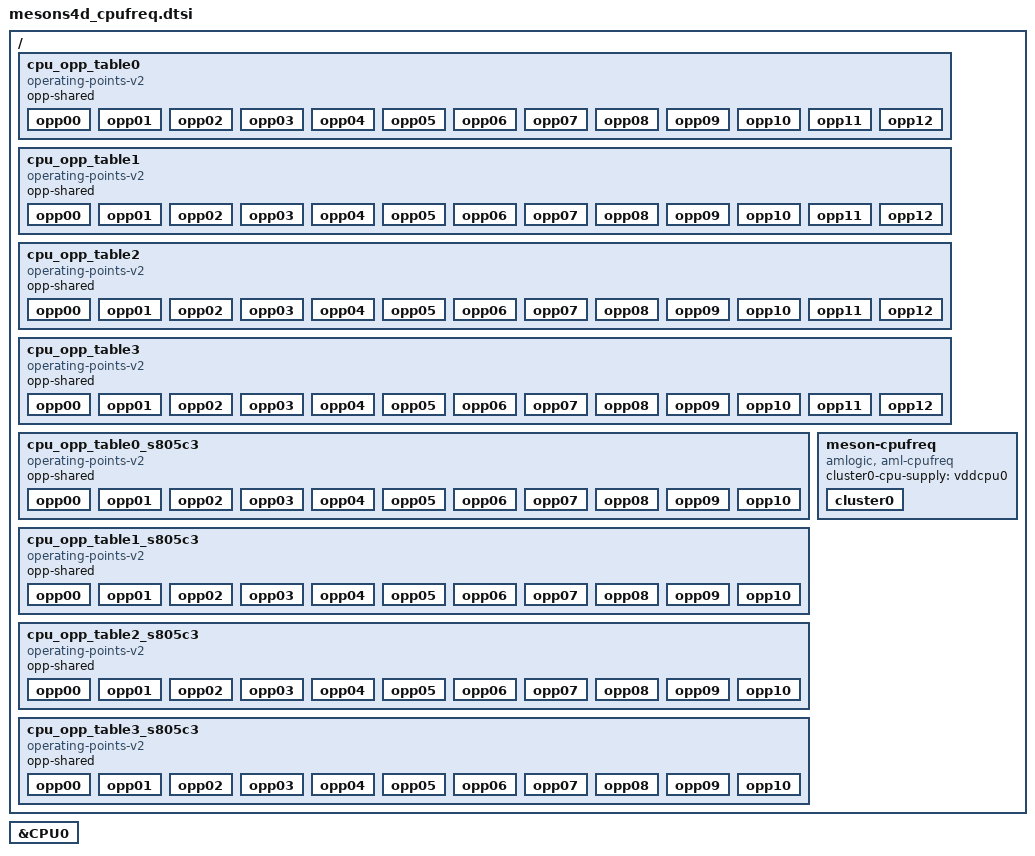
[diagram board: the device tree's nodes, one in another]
// SPDX-License-Identifier: (GPL-2.0+ OR MIT)
/*
 * Copyright (c) 2026 Amlogic, Inc. All rights reserved.
 */

/ {
	cpu_opp_table0: cpu_opp_table0 {
		compatible = "operating-points-v2";
		status = "okay";
		opp-shared;

		opp00 {
			opp-hz = /bits/ 64 <100000000>;
			opp-microvolt = <769000>;
		};
		opp01 {
			opp-hz = /bits/ 64 <250000000>;
			opp-microvolt = <769000>;
		};
		opp02 {
			opp-hz = /bits/ 64 <500000000>;
			opp-microvolt = <769000>;
		};
		opp03 {
			opp-hz = /bits/ 64 <666666666>;
			opp-microvolt = <769000>;
		};
		opp04 {
			opp-hz = /bits/ 64 <1000000000>;
			opp-microvolt = <769000>;
		};
		opp05 {
			opp-hz = /bits/ 64 <1200000000>;
			opp-microvolt = <769000>;
		};
		opp06 {
			opp-hz = /bits/ 64 <1404000000>;
			opp-microvolt = <799000>;
		};
		opp07 {
			opp-hz = /bits/ 64 <1500000000>;
			opp-microvolt = <829000>;
		};
		opp08 {
			opp-hz = /bits/ 64 <1608000000>;
			opp-microvolt = <859000>;
		};
		opp09 {
			opp-hz = /bits/ 64 <1704000000>;
			opp-microvolt = <889000>;
		};
		opp10 {
			opp-hz = /bits/ 64 <1800000000>;
			opp-microvolt = <929000>;
		};
		opp11 {
			opp-hz = /bits/ 64 <1908000000>;
			opp-microvolt = <979000>;
		};
		opp12 {
			opp-hz = /bits/ 64 <2004000000>;
			opp-microvolt = <1009000>;
		};
	};

	cpu_opp_table1: cpu_opp_table1 {
		compatible = "operating-points-v2";
		status = "okay";
		opp-shared;

		opp00 {
			opp-hz = /bits/ 64 <100000000>;
			opp-microvolt = <779000>;
		};
		opp01 {
			opp-hz = /bits/ 64 <250000000>;
			opp-microvolt = <779000>;
		};
		opp02 {
			opp-hz = /bits/ 64 <500000000>;
			opp-microvolt = <779000>;
		};
		opp03 {
			opp-hz = /bits/ 64 <666666666>;
			opp-microvolt = <779000>;
		};
		opp04 {
			opp-hz = /bits/ 64 <1000000000>;
			opp-microvolt = <779000>;
		};
		opp05 {
			opp-hz = /bits/ 64 <1200000000>;
			opp-microvolt = <779000>;
		};
		opp06 {
			opp-hz = /bits/ 64 <1404000000>;
			opp-microvolt = <799000>;
		};
		opp07 {
			opp-hz = /bits/ 64 <1500000000>;
			opp-microvolt = <829000>;
		};
		opp08 {
			opp-hz = /bits/ 64 <1608000000>;
			opp-microvolt = <859000>;
		};
		opp09 {
			opp-hz = /bits/ 64 <1704000000>;
			opp-microvolt = <889000>;
		};
		opp10 {
			opp-hz = /bits/ 64 <1800000000>;
			opp-microvolt = <929000>;
		};
		opp11 {
			opp-hz = /bits/ 64 <1908000000>;
			opp-microvolt = <979000>;
		};
		opp12 {
			opp-hz = /bits/ 64 <2004000000>;
			opp-microvolt = <1009000>;
		};
	};

	cpu_opp_table2: cpu_opp_table2 {
		compatible = "operating-points-v2";
		status = "okay";
		opp-shared;

		opp00 {
			opp-hz = /bits/ 64 <100000000>;
			opp-microvolt = <769000>;
		};
		opp01 {
			opp-hz = /bits/ 64 <250000000>;
			opp-microvolt = <769000>;
		};
		opp02 {
			opp-hz = /bits/ 64 <500000000>;
			opp-microvolt = <769000>;
		};
		opp03 {
			opp-hz = /bits/ 64 <666666666>;
			opp-microvolt = <769000>;
		};
		opp04 {
			opp-hz = /bits/ 64 <1000000000>;
			opp-microvolt = <769000>;
		};
		opp05 {
			opp-hz = /bits/ 64 <1200000000>;
			opp-microvolt = <769000>;
		};
		opp06 {
			opp-hz = /bits/ 64 <1404000000>;
			opp-microvolt = <779000>;
		};
		opp07 {
			opp-hz = /bits/ 64 <1500000000>;
			opp-microvolt = <789000>;
		};
		opp08 {
			opp-hz = /bits/ 64 <1608000000>;
			opp-microvolt = <819000>;
		};
		opp09 {
			opp-hz = /bits/ 64 <1704000000>;
			opp-microvolt = <859000>;
		};
		opp10 {
			opp-hz = /bits/ 64 <1800000000>;
			opp-microvolt = <879000>;
		};
		opp11 {
			opp-hz = /bits/ 64 <1908000000>;
			opp-microvolt = <939000>;
		};
		opp12 {
			opp-hz = /bits/ 64 <2004000000>;
			opp-microvolt = <989000>;
		};
	};

	cpu_opp_table3: cpu_opp_table3 {
		compatible = "operating-points-v2";
		status = "okay";
		opp-shared;

		opp00 {
			opp-hz = /bits/ 64 <100000000>;
			opp-microvolt = <759000>;
		};
		opp01 {
			opp-hz = /bits/ 64 <250000000>;
			opp-microvolt = <759000>;
		};
		opp02 {
			opp-hz = /bits/ 64 <500000000>;
			opp-microvolt = <759000>;
		};
		opp03 {
			opp-hz = /bits/ 64 <666666666>;
			opp-microvolt = <759000>;
		};
		opp04 {
			opp-hz = /bits/ 64 <1000000000>;
			opp-microvolt = <759000>;
		};
		opp05 {
			opp-hz = /bits/ 64 <1200000000>;
			opp-microvolt = <759000>;
		};
		opp06 {
			opp-hz = /bits/ 64 <1404000000>;
			opp-microvolt = <759000>;
		};
		opp07 {
			opp-hz = /bits/ 64 <1500000000>;
			opp-microvolt = <779000>;
		};
		opp08 {
			opp-hz = /bits/ 64 <1608000000>;
			opp-microvolt = <799000>;
		};
		opp09 {
			opp-hz = /bits/ 64 <1704000000>;
			opp-microvolt = <819000>;
		};
		opp10 {
			opp-hz = /bits/ 64 <1800000000>;
			opp-microvolt = <869000>;
		};
		opp11 {
			opp-hz = /bits/ 64 <1908000000>;
			opp-microvolt = <919000>;
		};
		opp12 {
			opp-hz = /bits/ 64 <2004000000>;
			opp-microvolt = <959000>;
		};
	};

	cpu_opp_table0_s805c3: cpu_opp_table0_s805c3 {
		compatible = "operating-points-v2";
		status = "okay";
		opp-shared;

		opp00 {
			opp-hz = /bits/ 64 <100000000>;
			opp-microvolt = <769000>;
		};
		opp01 {
			opp-hz = /bits/ 64 <250000000>;
			opp-microvolt = <769000>;
		};
		opp02 {
			opp-hz = /bits/ 64 <500000000>;
			opp-microvolt = <769000>;
		};
		opp03 {
			opp-hz = /bits/ 64 <666666666>;
			opp-microvolt = <769000>;
		};
		opp04 {
			opp-hz = /bits/ 64 <1000000000>;
			opp-microvolt = <769000>;
		};
		opp05 {
			opp-hz = /bits/ 64 <1200000000>;
			opp-microvolt = <769000>;
		};
		opp06 {
			opp-hz = /bits/ 64 <1404000000>;
			opp-microvolt = <799000>;
		};
		opp07 {
			opp-hz = /bits/ 64 <1500000000>;
			opp-microvolt = <829000>;
		};
		opp08 {
			opp-hz = /bits/ 64 <1608000000>;
			opp-microvolt = <859000>;
		};
		opp09 {
			opp-hz = /bits/ 64 <1704000000>;
			opp-microvolt = <889000>;
		};
		opp10 {
			opp-hz = /bits/ 64 <1800000000>;
			opp-microvolt = <929000>;
		};
	};

	cpu_opp_table1_s805c3: cpu_opp_table1_s805c3 {
		compatible = "operating-points-v2";
		status = "okay";
		opp-shared;

		opp00 {
			opp-hz = /bits/ 64 <100000000>;
			opp-microvolt = <779000>;
		};
		opp01 {
			opp-hz = /bits/ 64 <250000000>;
			opp-microvolt = <779000>;
		};
		opp02 {
			opp-hz = /bits/ 64 <500000000>;
			opp-microvolt = <779000>;
		};
		opp03 {
			opp-hz = /bits/ 64 <666666666>;
			opp-microvolt = <779000>;
		};
		opp04 {
			opp-hz = /bits/ 64 <1000000000>;
			opp-microvolt = <779000>;
		};
		opp05 {
			opp-hz = /bits/ 64 <1200000000>;
			opp-microvolt = <779000>;
		};
		opp06 {
			opp-hz = /bits/ 64 <1404000000>;
			opp-microvolt = <799000>;
		};
		opp07 {
			opp-hz = /bits/ 64 <1500000000>;
			opp-microvolt = <829000>;
		};
		opp08 {
			opp-hz = /bits/ 64 <1608000000>;
			opp-microvolt = <859000>;
		};
		opp09 {
			opp-hz = /bits/ 64 <1704000000>;
			opp-microvolt = <889000>;
		};
		opp10 {
			opp-hz = /bits/ 64 <1800000000>;
			opp-microvolt = <929000>;
		};
	};

	cpu_opp_table2_s805c3: cpu_opp_table2_s805c3 {
		compatible = "operating-points-v2";
		status = "okay";
		opp-shared;

		opp00 {
			opp-hz = /bits/ 64 <100000000>;
			opp-microvolt = <769000>;
		};
		opp01 {
			opp-hz = /bits/ 64 <250000000>;
			opp-microvolt = <769000>;
		};
		opp02 {
			opp-hz = /bits/ 64 <500000000>;
			opp-microvolt = <769000>;
		};
		opp03 {
			opp-hz = /bits/ 64 <666666666>;
			opp-microvolt = <769000>;
		};
		opp04 {
			opp-hz = /bits/ 64 <1000000000>;
			opp-microvolt = <769000>;
		};
		opp05 {
			opp-hz = /bits/ 64 <1200000000>;
			opp-microvolt = <769000>;
		};
		opp06 {
			opp-hz = /bits/ 64 <1404000000>;
			opp-microvolt = <779000>;
		};
		opp07 {
			opp-hz = /bits/ 64 <1500000000>;
			opp-microvolt = <789000>;
		};
		opp08 {
			opp-hz = /bits/ 64 <1608000000>;
			opp-microvolt = <819000>;
		};
		opp09 {
			opp-hz = /bits/ 64 <1704000000>;
			opp-microvolt = <859000>;
		};
		opp10 {
			opp-hz = /bits/ 64 <1800000000>;
			opp-microvolt = <879000>;
		};
	};

	cpu_opp_table3_s805c3: cpu_opp_table3_s805c3 {
		compatible = "operating-points-v2";
		status = "okay";
		opp-shared;

		opp00 {
			opp-hz = /bits/ 64 <100000000>;
			opp-microvolt = <759000>;
		};
		opp01 {
			opp-hz = /bits/ 64 <250000000>;
			opp-microvolt = <759000>;
		};
		opp02 {
			opp-hz = /bits/ 64 <500000000>;
			opp-microvolt = <759000>;
		};
		opp03 {
			opp-hz = /bits/ 64 <666666666>;
			opp-microvolt = <759000>;
		};
		opp04 {
			opp-hz = /bits/ 64 <1000000000>;
			opp-microvolt = <759000>;
		};
		opp05 {
			opp-hz = /bits/ 64 <1200000000>;
			opp-microvolt = <759000>;
		};
		opp06 {
			opp-hz = /bits/ 64 <1404000000>;
			opp-microvolt = <759000>;
		};
		opp07 {
			opp-hz = /bits/ 64 <1500000000>;
			opp-microvolt = <779000>;
		};
		opp08 {
			opp-hz = /bits/ 64 <1608000000>;
			opp-microvolt = <799000>;
		};
		opp09 {
			opp-hz = /bits/ 64 <1704000000>;
			opp-microvolt = <819000>;
		};
		opp10 {
			opp-hz = /bits/ 64 <1800000000>;
			opp-microvolt = <869000>;
		};
	};

	meson-cpufreq {
		compatible = "amlogic, aml-cpufreq";
		status = "okay";

		cluster0-cpu-supply = <&vddcpu0>;

		cluster0 {
			clocks = <&scmi_clk CLKID_CPU_CLK>;
			clock-names = "cpuclk";
			voltage-tolerance = <0>;
			transition_delay_us = <10000>;
			cluster_cores = <0 1 2 3>;
			pdvfs_enabled;
		};
	};
};/* end of / */

&CPU0 {
	operating-points-v2 = <&cpu_opp_table0>,
			      <&cpu_opp_table1>,
			      <&cpu_opp_table2>,
			      <&cpu_opp_table3>;
};
